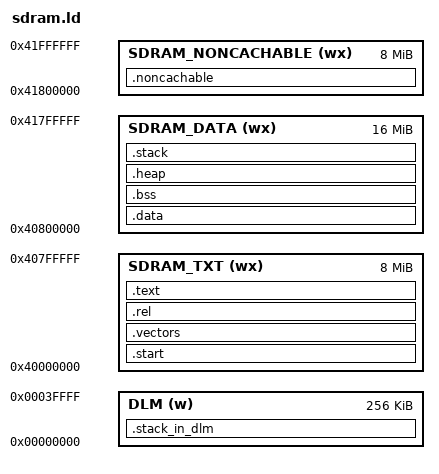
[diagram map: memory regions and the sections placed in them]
/*
 * Copyright 2021 hpmicro
 * SPDX-License-Identifier: BSD-3-Clause
 */

ENTRY(_start)

STACK_SIZE = DEFINED(_stack_size) ? _stack_size : 0x4000;
HEAP_SIZE = DEFINED(_heap_size) ? _heap_size : 0x4000;

MEMORY
{
    DLM (w) : ORIGIN = 0, LENGTH = 256K
    SDRAM_TXT (wx) : ORIGIN = 0x40000000, LENGTH = 8M
    SDRAM_DATA (wx) : ORIGIN = 0x40800000, LENGTH = 16M
    SDRAM_NONCACHABLE (wx) : ORIGIN = 0x41800000, LENGTH = 8M
}

SECTIONS
{
    .start : {
        . = ALIGN(8);
        KEEP(*(.start))
    } > SDRAM_TXT

    .vectors : {
        . = ALIGN(8);
        KEEP(*(.isr_vector))
        KEEP(*(.vector_table))
        . = ALIGN(8);
    } > SDRAM_TXT 

    .rel : {
        KEEP(*(.rel*))
    } > SDRAM_TXT

    .text : {
        . = ALIGN(8);
        *(.text)
        *(.text*)
        *(.rodata)
        *(.rodata*)
        *(.srodata)
        *(.srodata*)

        *(.hash)
        *(.dyn*)
        *(.gnu*)
        *(.pl*)

        KEEP(*(.eh_frame))
        *(.eh_frame*)

        KEEP (*(.init))
        KEEP (*(.fini))
        . = ALIGN(8);

        PROVIDE (__etext = .);
        PROVIDE (_etext = .);
        PROVIDE (etext = .);
    } > SDRAM_TXT 

    .data : AT(etext) {
        . = ALIGN(8);
        __data_start__ = .;
        *(.data)
        *(.data*)
        *(.sdata)
        *(.sdata*)
        *(.tdata)
        *(.tdata*)

        KEEP(*(.jcr))
        KEEP(*(.dynamic))
        KEEP(*(.got*))
        KEEP(*(.got))

        KEEP(*(.gcc_except_table))
        KEEP(*(.gcc_except_table.*))

        . = ALIGN(8);
        PROVIDE(__preinit_array_start = .);
        KEEP(*(.preinit_array))
        PROVIDE(__preinit_array_end = .);

        . = ALIGN(8);
        PROVIDE(__init_array_start = .);
        KEEP(*(SORT_BY_INIT_PRIORITY(.init_array.*)))
        KEEP(*(.init_array))
        PROVIDE(__init_array_end = .);

        . = ALIGN(8);
        PROVIDE(__finit_array_start = .);
        KEEP(*(SORT_BY_INIT_PRIORITY(.finit_array.*)))
        KEEP(*(.finit_array))
        PROVIDE(__finit_array_end = .);

        . = ALIGN(8);
        KEEP(*crtbegin*.o(.ctors))
        KEEP(*(EXCLUDE_FILE (*crtend*.o) .ctors))
        KEEP(*(SORT(.ctors.*)))
        KEEP(*(.ctors))

        . = ALIGN(8);
        KEEP(*crtbegin*.o(.dtors))
        KEEP(*(EXCLUDE_FILE (*crtend*.o) .dtors))
        KEEP(*(SORT(.dtors.*)))
        KEEP(*(.dtors))

        . = ALIGN(8);
        __data_end__ = .;
        PROVIDE (__edata = .);
        PROVIDE (_edata = .);
        PROVIDE (edata = .);
    } > SDRAM_DATA 

    .bss : {
        . = ALIGN(8);
        __bss_start__ = .;
        *(.bss)
        *(.bss*)
        *(.tbss*)
        *(.sbss*)
        *(.scommon)
        *(.scommon*)
        *(.tcommon*)
        *(.dynsbss*)
        *(COMMON)
        . = ALIGN(8);
        _end = .;
        __bss_end__ = .;
    } > SDRAM_DATA

    .heap : {
        . = ALIGN(8);
        __heap_start__ = .;
        . += HEAP_SIZE;
        __heap_end__ = .;
    } > SDRAM_DATA

    .stack : {
        . = ALIGN(8);
        __stack_base__ = .;
        . += STACK_SIZE;
        PROVIDE (_stack = .);
        __freertos_irq_stack_top = .;
    } > SDRAM_DATA

    .noncachable (NOLOAD) : {
        . = ALIGN(8);
        KEEP(*(.framebuffer))
        KEEP(*(.noncachable))
        . = ALIGN(8);
    } > SDRAM_NONCACHABLE 

    /* this section is only for external ram initialization */
    .stack_in_dlm : {
        . = ALIGN(8);
        . += 1024;
        _stack_in_dlm = .;
    } > DLM

    __noncachable_start__ = ORIGIN(SDRAM_NONCACHABLE);
    __noncachable_end__ = ORIGIN(SDRAM_NONCACHABLE) + LENGTH(SDRAM_NONCACHABLE);

    ASSERT(__stack_base__ >= __heap_end__, "stack overlapped with heap")
}
